# 3065PNPIRA register map
File version: 1.0
Registers are 32-bit, access per field, reset 0x0 unless marked. A register's access mark holds for its fields unless they carry their own. Offsets are from the block's base; [hi:lo] are bit positions; {n}, {i} and the like mark numbered series; 'fields as' and 'values as' point back to an identical list.

## IOCMG_AON — IOCMG_AON peripheral interface
Base 0x147F0000
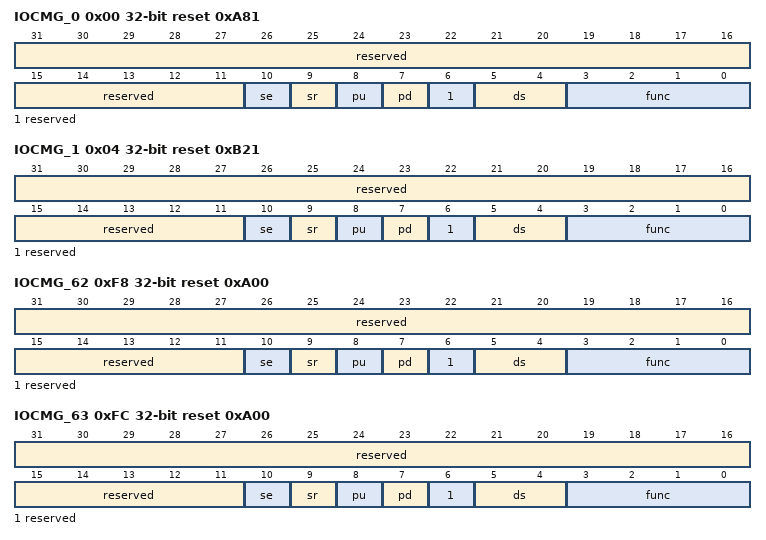
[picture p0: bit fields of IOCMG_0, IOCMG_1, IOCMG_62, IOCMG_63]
0x00 IOCMG_0 reset 0xA81 — IOCMG_0为TCK/SWDCK管脚配置寄存器。
  [31:11] reserved ro — 保留。
  [10] se rw — 管脚施密特输入控制。 0：关闭； 1：打开。
  [9] sr rw — 管脚电平转换速率控制。 0：快沿输出； 1：慢沿输出。
  [8] pu rw — 管脚上拉控制。 0：关闭； 1：打开。
  [7] pd rw — 管脚下拉控制。 0：关闭； 1：打开。
  [6] reserved ro — 保留。
  [5:4] ds rw — 管脚驱动能力选择（档位越大，驱动能力越大）。 00：档位1； 01：档位2； 10：档位3； 11：档位4。
  [3:0] func rw — 管脚复用功能选择。 具体复用功能请参考《3066M / 3065P系列数据手册》。
0x04 IOCMG_1 reset 0xB21 — IOCMG_1为TMS/SWDIO管脚配置寄存器。
  fields as IOCMG_0
0xF8 IOCMG_62 reset 0xA00 — IOCMG_62为I2C0_SCL/UART2_TX管脚配置寄存器。
  fields as IOCMG_0
0xFC IOCMG_63 reset 0xA00 — IOCMG_63为I2C0_SDA/UART2_RX管脚配置寄存器。
  fields as IOCMG_0
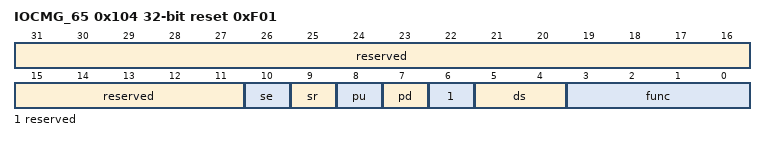
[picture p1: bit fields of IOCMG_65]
0x104 IOCMG_65 reset 0xF01 — IOCMG_65为RESETN管脚配置寄存器。
  fields as IOCMG_0

## GPIO0 — GPIO0 peripheral interface
Base 0x14500000
Same registers: GPIO{n} {0x14500000+0x1000*n} (n=1..9)
{0x0+4i} GPIO_DATA{i} (i=0..255) 8-bit rw — GPIO_DATA为GPIO数据寄存器，用来对输入或输出数据进行缓存。
  [7:0] gpio_data — 当GPIO配置为输入模式时，为GPIO输入数据；当GPIO配置为输出模式时，为输出数据。各比特均可独立控制。与GPIO_DIR配合使用。
0x400 GPIO_DIR 8-bit rw — GPIO_DIR为GPIO方向控制寄存器。用来配置GPIO方向。
  [7:0] gpio_dir — GPIO方向控制寄存器。bit[7:0]分别对应GPIO_DATA[7:0]，各比特可独立控制。 0：输入； 1：输出。
0x404 GPIO_IS 8-bit rw — GPIO_IS为GPIO中断触发寄存器。用来配置GPIO触发电平方式。
  [7:0] gpio_is — GPIO中断触发控制寄存器，bit[7:0]分别对应GPIO_DATAbit[7:0]，各比特独立控制。 0：边沿触发中断； 1：电平触发中断。
0x408 GPIO_IBE 8-bit rw — GPIO_IBE为GPIO双沿触发中断寄存器。用来配置GPIO沿触发方式。
  [7:0] gpio_ibe — GPIO中断沿触发控制寄存器，bit[7:0]分别对应GPIO_DATAbit[7:0]，各比特独立控制。 0：单边沿触发中断，具体是上升沿还是下降沿触发由GPIO_IEV控制； 1：双边触发中断。
0x40C GPIO_IEV 8-bit rw — GPIO_IEV为GPIO触发中断条件寄存器。用来配置GPIO触发中断条件。
  [7:0] gpio_iev — GPIO触发中断条件寄存器，bit[7:0]分别对应GPIO_DATAbit[7:0]，各比特独立控制。 0：下降沿或低电平触发中断，具体由GPIO_IS控制； 1：上升沿或高电平触发中断。
0x410 GPIO_IE 8-bit rw — GPIO_IE为GPIO中断屏蔽寄存器。用来屏蔽GPIO中断。
  [7:0] gpio_ie — GPIO中断屏蔽寄存器，bit[7:0]分别对应GPIO_DATAbit[7:0]，各比特独立控制。 0：屏蔽中断； 1：不屏蔽中断。
0x414 GPIO_RIS 8-bit ro — GPIO_RIS为GPIO原始中断状态寄存器。用来查询GPIO原始中断状态。
  [7:0] gpio_ris — GPIO原始中断寄存器，bit[7:0]分别对应GPIO_DATAbit[7:0]，指示未屏蔽的中断状态。该状态不受GPIO_IE寄存器屏蔽控制。 0：未发生中断； 1：已发生中断。
0x418 GPIO_MIS 8-bit ro — GPIO_MIS为GPIO屏蔽状态中断寄存器。用来查询GPIO屏蔽后的中断状态。对所有位进行或操作得到中断输出gpio_int。
  [7:0] gpio_mis — GPIO屏蔽后中断寄存器，bit[7:0]分别对应GPIO_DATAbit[7:0]，指示经屏蔽后的中断状态。该状态受GPIO_IE寄存器屏蔽控制。 0：中断无效； 1：中断有效。
0x41C GPIO_IC 8-bit rw — GPIO_IC为GPIO中断清除寄存器。用来清除GPIO产生的中断，同时清除GPIO_RIS寄存器和GPIO_MIS寄存器。
  [7:0] gpio_ic write-clears — GPIO中断清除寄存器，bit[7:0]分别对应GPIO_DATAbit[7:0]，各比特可独立控制。 0：无影响； 1：清除中断。

## SYSCTRL0 — SYSCTRL0 peripheral interface
Base 0x10100000
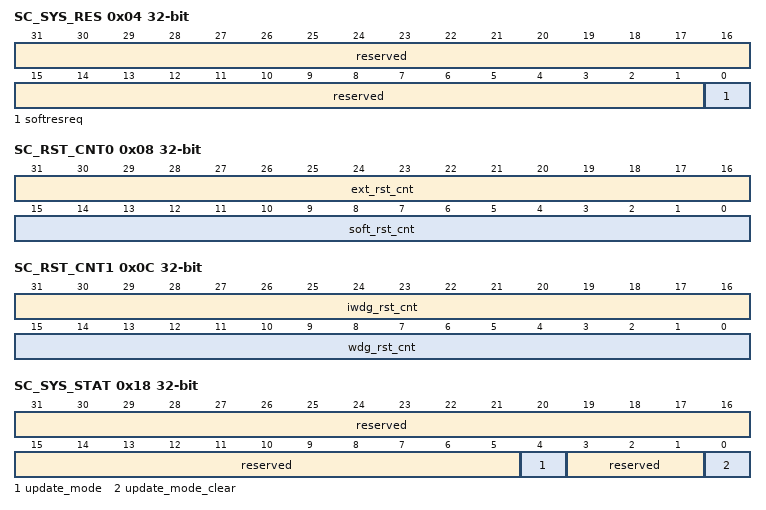
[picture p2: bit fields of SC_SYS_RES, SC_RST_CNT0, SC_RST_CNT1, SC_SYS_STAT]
0x04 SC_SYS_RES — SC_SYS_RES为系统软件复位寄存器。 该寄存器受写保护控制，由寄存器SC_LOCKEN[sc_cfg_lock]决定。只有写使能时，对此寄存器的写操作才有效。
  [31:1] reserved ro — 保留。
  [0] softresreq rw — 对此寄存器位域的任意写操作都会导致系统软复位。
0x08 SC_RST_CNT0 ro — SC_RST_CNT0为复位次数统计寄存器0。
  [31:16] ext_rst_cnt — RESETN管脚复位次数统计。
  [15:0] soft_rst_cnt — 软复位次数统计。
0x0C SC_RST_CNT1 ro — SC_RST_CNT1为复位次数统计寄存器1。
  [31:16] iwdg_rst_cnt — iwdg复位次数统计。
  [15:0] wdg_rst_cnt — wdg复位次数统计。
0x18 SC_SYS_STAT — SC_SYS_STAT为系统启动模式寄存器。
  [31:5] reserved ro — 保留。
  [4] update_mode ro — 系统升级标识，MCU上电时锁存。 0：不升级，直接启动模式； 1：升级模式。 注：当处于升级模式时，MCU JTAG相关管脚强制为JTAG功能，无法软件切换为其他复用功能。
  [3:1] reserved ro — 保留。
  [0] update_mode_clear rw — 系统升级标识清除寄存器，MCU上电完成后生效。 0：不清除； 1：清除。
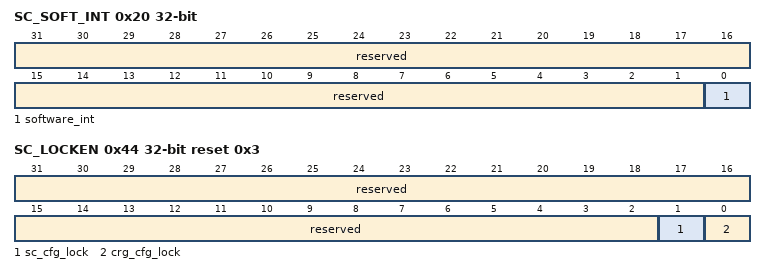
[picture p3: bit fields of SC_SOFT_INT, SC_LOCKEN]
0x20 SC_SOFT_INT — SC_SOFT_INT为软件中断寄存器。
  [31:1] reserved ro — 保留。
  [0] software_int rw — 软件中断寄存器。 0：清除中断； 1：产生中断。
0x24 SC_SOFT_EVT_ID rw — SC_SOFT_EVT_ID为软中断事件ID寄存器。
  [31:0] swint_evt_id — 软中断事件ID，可用于软中断事件类型定义。
0x44 SC_LOCKEN reset 0x3 — SC_LOCKEN为关键寄存器的写保护控制寄存器。 仅当word写操作数的[31:16]位域为0xEA51时，才能对此寄存器的[15:0]位域进行写操作。
  [31:2] reserved ro — 保留。
  [1] sc_cfg_lock rw — SYSCTRL相关寄存器写保护。 0：写使能； 1：写禁止。
  [0] crg_cfg_lock rw — CRG相关寄存器写保护。 0：写使能； 1：写禁止。
0x200 SC_HRST_REG0 rw — SC_HRST_REG0为SC专用硬复位寄存器0。 该寄存器不会被系统软件复位所复位。
  [31:0] sc_hrst_reg0 — 系统正常启动流程中，如果检测到此寄存器值为0xA5A5A5A5，则CPU将停止启动系统，此时可以通过JTAG/SWD接口调试（或烧写）。
0xE00 USER_POR_REG0 rw — USER_POR_REG0为USER专用POR复位寄存器0。 该寄存器仅被POR复位或从低功耗模式唤醒时复位。
  [31:0] user_por_reg0 — USER专用REG0。
0xE04 USER_POR_REG1 rw — USER_POR_REG1为USER专用POR复位寄存器1。 该寄存器仅被POR复位或从低功耗模式唤醒时复位。
  [31:0] user_por_reg1 — USER专用REG1。
0xE40 USER_HRST_REG0 rw — USER_HRST_REG0为USER专用硬复位寄存器0。 该寄存器不会被系统软复位所复位。
  [31:0] user_hrst_reg0 — USER专用REG2。
0xE44 USER_HRST_REG1 rw — USER_HRST_REG1为USER专用硬复位寄存器1。 该寄存器不会被系统软复位所复位。
  [31:0] user_hrst_reg1 — USER专用REG3。
0xE80 USER_REG0 rw — USER_REG0为USER专用寄存器0。
  [31:0] user_reg0 — USER专用REG4。
0xE84 USER_REG1 rw — USER_REG1为USER专用寄存器1。
  [31:0] user_reg1 — USER专用REG5。
